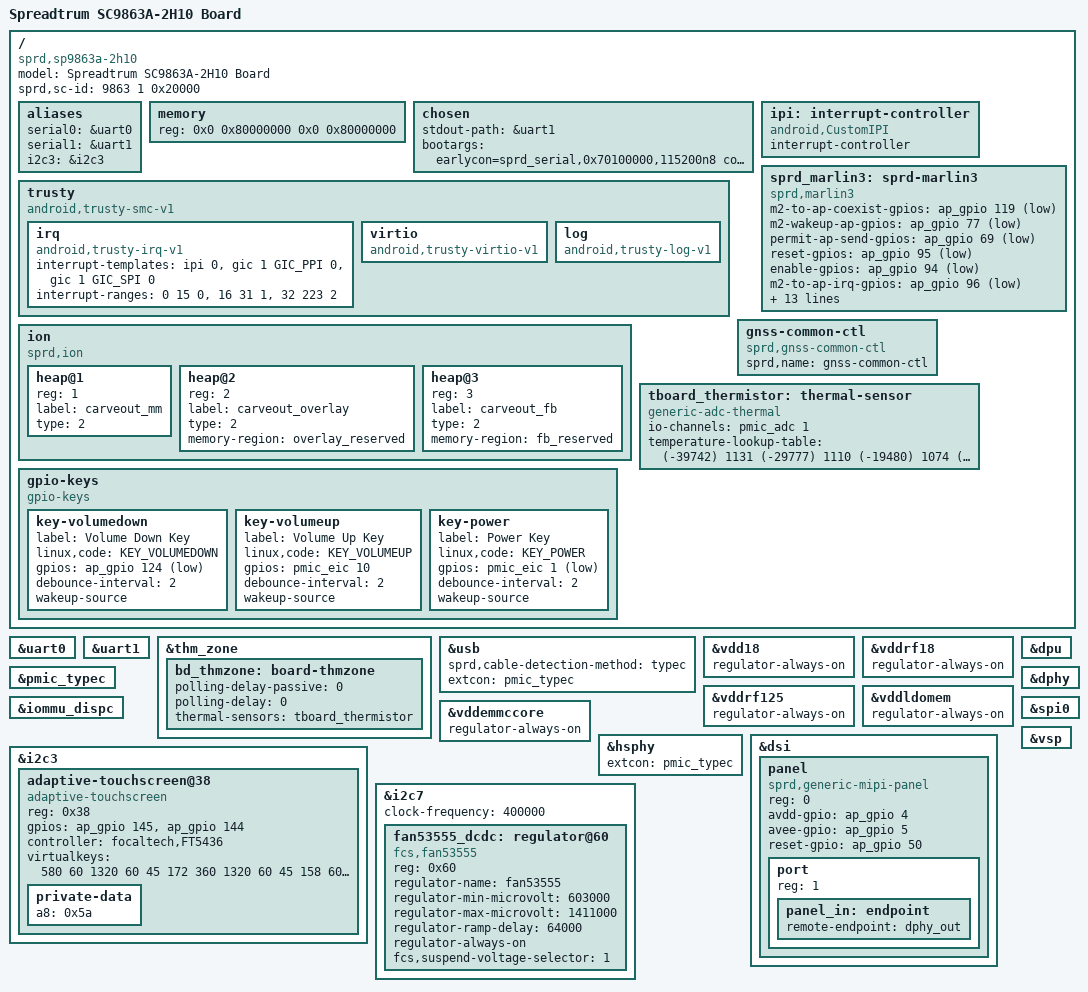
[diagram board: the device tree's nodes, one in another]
// SPDX-License-Identifier: (GPL-2.0+ OR MIT)
/*
 * Spreadtrum Sharkl3 platform DTS file
 *
 * Copyright (C) 2018, Spreadtrum Communications Inc.
 */

/dts-v1/;

#include "sc9863a.dtsi"
#include "sp9863a-common.dtsi"
#include "lcd/lcd_nt35695_truly_mipi_fhd.dtsi"
#include "lcd/lcd_nt35532_truly_mipi_fhd.dtsi"
#include "lcd/lcd_nt35596_boe_mipi_fhd.dtsi"
#include <dt-bindings/gpio/gpio.h>
#include <dt-bindings/input/input.h>

/ {
	model = "Spreadtrum SC9863A-2H10 Board";

	compatible = "sprd,sp9863a-2h10", "sprd,sc9863a";

	sprd,sc-id = <9863 1 0x20000>;

	aliases {
		serial0 = &uart0;
		serial1 = &uart1;
		i2c3 = &i2c3;
	};

	memory: memory {
		device_type = "memory";
		reg = <0x0 0x80000000 0x0 0x80000000>;
	};

	chosen {
		stdout-path = &uart1;
		bootargs = "earlycon=sprd_serial,0x70100000,115200n8 console=ttyS1,115200n8 loglevel=1 init=/init root=/dev/mmcblk0p30 rootfstype=ext4 ro rootwait androidboot.selinux=permissive androidboot.hardware=s9863a2h10 androidboot.dtbo_idx=0 printk.devkmsg=on";
	};

	ipi: interrupt-controller {
		compatible = "android,CustomIPI";
		#interrupt-cells = <1>;
		interrupt-controller;
	};

	trusty {
		compatible = "android,trusty-smc-v1";

		irq {
			compatible = "android,trusty-irq-v1";
			interrupt-templates = <&ipi 0>,
						<&gic 1 GIC_PPI 0>,
						<&gic 1 GIC_SPI 0>;
			interrupt-ranges = < 0  15 0>,
						<16  31 1>,
						<32 223 2>;
		};

		virtio {
			compatible = "android,trusty-virtio-v1";
		};

		log {
			compatible = "android,trusty-log-v1";
		};
	};

	ion {
		compatible = "sprd,ion";
		#address-cells = <1>;
		#size-cells = <0>;

		heap@1 {
			reg = <1>;
			label = "carveout_mm";
			type = <2>;
		};

		heap@2 {
			reg = <2>;
			label = "carveout_overlay";
			type = <2>;
			memory-region = <&overlay_reserved>;
		};

		heap@3 {
			reg = <3>;
			label = "carveout_fb";
			type = <2>;
			memory-region = <&fb_reserved>;
		};
	};

	sprd_marlin3: sprd-marlin3 {
		compatible = "sprd,marlin3";
		m2-to-ap-coexist-gpios = <&ap_gpio 119 GPIO_ACTIVE_LOW>;
		m2-wakeup-ap-gpios = <&ap_gpio 77 GPIO_ACTIVE_LOW>;
		permit-ap-send-gpios = <&ap_gpio 69 GPIO_ACTIVE_LOW>;
		reset-gpios = <&ap_gpio 95 GPIO_ACTIVE_LOW>;
		enable-gpios = <&ap_gpio 94 GPIO_ACTIVE_LOW>;
		m2-to-ap-irq-gpios = <&ap_gpio 96 GPIO_ACTIVE_LOW>;
		dvdd12-supply = <&vddcon>;
		avdd12-supply = <&vddcon>;
		avdd33-supply = <&vddwifipa>;
		dcxo18-supply = <&vddkpled>;
		clock-names = "clk_32k","source","enable";
		clocks = <&aon_clk CLK_AUX0>,
			 <&ext_32k>,
			 <&aonapb_gate CLK_AUX0_EB>;
		sprd,btwf-file-name = "/dev/block/platform/soc/soc:ap-ahb/20600000.sdio/by-name/wcnmodem";
		sprd,gnss-file-name = "/dev/block/platform/soc/soc:ap-ahb/20600000.sdio/by-name/gnssmodem";
		adma-tx;
		adma-rx;
		post-power-on-delay-ms = <20>;
	};

	gnss-common-ctl {
		compatible = "sprd,gnss-common-ctl";
		sprd,name = "gnss-common-ctl";
	};

	gpio-keys {
		compatible = "gpio-keys";

		key-volumedown {
			label = "Volume Down Key";
			linux,code = <KEY_VOLUMEDOWN>;
			gpios = <&ap_gpio 124 GPIO_ACTIVE_LOW>;
			debounce-interval = <2>;
			wakeup-source;
		};

		key-volumeup {
			label = "Volume Up Key";
			linux,code = <KEY_VOLUMEUP>;
			gpios = <&pmic_eic 10 GPIO_ACTIVE_HIGH>;
			debounce-interval = <2>;
			wakeup-source;
		};

		key-power {
			label = "Power Key";
			linux,code = <KEY_POWER>;
			gpios = <&pmic_eic 1 GPIO_ACTIVE_LOW>;
			debounce-interval = <2>;
			wakeup-source;
		};
	};

	tboard_thermistor:thermal-sensor {
		compatible = "generic-adc-thermal";
		#thermal-sensor-cells = <0>;
		io-channels = <&pmic_adc 1>;
		io-channel-names = "sensor-channel";
		temperature-lookup-table = <	(-39742) 1131
						(-29777) 1110
						(-19480) 1074
						(-4679) 983
						10110 838
						24805 654
						44922 413
						54903 316
						64895 238
						74884 178
						84883 133
						94883 100
						104880 75
						114889 57
						124872 43 >;
	};
};

&uart0 {
	status = "okay";
};

&uart1 {
	status = "okay";
};

&thm_zone {
	bd_thmzone: board-thmzone {
		polling-delay-passive = <0>;
		polling-delay = <0>;
		thermal-sensors = <&tboard_thermistor>;
	};
};

&usb {
	sprd,cable-detection-method = "typec";
};

&vdd18 {
	regulator-always-on;
};

&vddrf18 {
	regulator-always-on;
};

&vddrf125 {
	regulator-always-on;
};

&vddldomem {
	regulator-always-on;
};

&vddemmccore {
	regulator-always-on;
};

&hsphy {
	extcon = <&pmic_typec>;
};

&usb {
	extcon = <&pmic_typec>;
};

&pmic_typec {
	status = "okay";
};

&dpu {
	status = "okay";
};

&iommu_dispc {
	status = "okay";
};

&dsi {
	status = "okay";
	#address-cells = <1>;
	#size-cells = <0>;

	panel: panel {
		compatible = "sprd,generic-mipi-panel";
		#address-cells = <1>;
		#size-cells = <0>;
		reg = <0>;

		avdd-gpio = <&ap_gpio 4 GPIO_ACTIVE_HIGH>;
		avee-gpio = <&ap_gpio 5 GPIO_ACTIVE_HIGH>;
		reset-gpio = <&ap_gpio 50 GPIO_ACTIVE_HIGH>;
		port {
			reg = <1>;
			panel_in: endpoint {
				remote-endpoint = <&dphy_out>;
			};
		};
	};
};

&dphy {
	status = "okay";
};

&i2c3 {
	status = "okay";

	adaptive-touchscreen@38 {
		compatible = "adaptive-touchscreen";
		reg = <0x38>;
		gpios = <&ap_gpio 145 GPIO_ACTIVE_HIGH
			&ap_gpio 144 GPIO_ACTIVE_HIGH>;
		controller = "focaltech,FT5436";
		virtualkeys = <580 60 1320 60 45
			172 360 1320 60 45
			158 600 1320 60 45>;
		private-data {
			a8 = /bits/ 8 <0x5a>;
		};
	};
};

&i2c7 {
	status = "okay";
	clock-frequency = <400000>;

	fan53555_dcdc: regulator@60 {
		compatible = "fcs,fan53555";
		reg = <0x60>;
		regulator-name = "fan53555";
		regulator-min-microvolt = <603000>;
		regulator-max-microvolt = <1411000>;
		regulator-ramp-delay = <64000>;
		regulator-always-on;
		fcs,suspend-voltage-selector = <1>;
	};
};

&spi0 {
	/*used for fingerprint sensor*/
	status = "okay";
};

&vsp {
	status = "okay";
};
